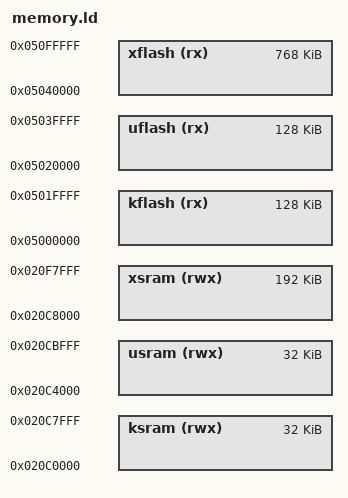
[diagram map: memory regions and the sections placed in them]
/****************************************************************************
 * configs/lc823450-xgevk/scripts/memory.ld
 *
 *   Copyright 2018 Sony Video & Sound Products Inc.
 *   Author: Masayuki Ishikawa <Masayuki.Ishikawa@jp.sony.com>
 *
 * Based on configs/stm32f4discovery/scripts/memory.ld
 *
 * Redistribution and use in source and binary forms, with or without
 * modification, are permitted provided that the following conditions
 * are met:
 *
 * 1. Redistributions of source code must retain the above copyright
 *    notice, this list of conditions and the following disclaimer.
 * 2. Redistributions in binary form must reproduce the above copyright
 *    notice, this list of conditions and the following disclaimer in
 *    the documentation and/or other materials provided with the
 *    distribution.
 * 3. Neither the name NuttX nor the names of its contributors may be
 *    used to endorse or promote products derived from this software
 *    without specific prior written permission.
 *
 * THIS SOFTWARE IS PROVIDED BY THE COPYRIGHT HOLDERS AND CONTRIBUTORS
 * "AS IS" AND ANY EXPRESS OR IMPLIED WARRANTIES, INCLUDING, BUT NOT
 * LIMITED TO, THE IMPLIED WARRANTIES OF MERCHANTABILITY AND FITNESS
 * FOR A PARTICULAR PURPOSE ARE DISCLAIMED. IN NO EVENT SHALL THE
 * COPYRIGHT OWNER OR CONTRIBUTORS BE LIABLE FOR ANY DIRECT, INDIRECT,
 * INCIDENTAL, SPECIAL, EXEMPLARY, OR CONSEQUENTIAL DAMAGES (INCLUDING,
 * BUT NOT LIMITED TO, PROCUREMENT OF SUBSTITUTE GOODS OR SERVICES; LOSS
 * OF USE, DATA, OR PROFITS; OR BUSINESS INTERRUPTION) HOWEVER CAUSED
 * AND ON ANY THEORY OF LIABILITY, WHETHER IN CONTRACT, STRICT
 * LIABILITY, OR TORT (INCLUDING NEGLIGENCE OR OTHERWISE) ARISING IN
 * ANY WAY OUT OF THE USE OF THIS SOFTWARE, EVEN IF ADVISED OF THE
 * POSSIBILITY OF SUCH DAMAGE.
 *
 ****************************************************************************/

MEMORY
{
    /* 1024Kb FLASH (tentative) */

    kflash (rx)      : ORIGIN = 0x05000000, LENGTH = 128K
    uflash (rx)      : ORIGIN = 0x05020000, LENGTH = 128K
    xflash (rx)      : ORIGIN = 0x05040000, LENGTH = 768K

    /* 256Kb SRAM (tentative) */

    ksram (rwx)      : ORIGIN = 0x020c0000, LENGTH = 32K
    usram (rwx)      : ORIGIN = 0x020c4000, LENGTH = 32K
    xsram (rwx)      : ORIGIN = 0x020c8000, LENGTH = 192K
}
